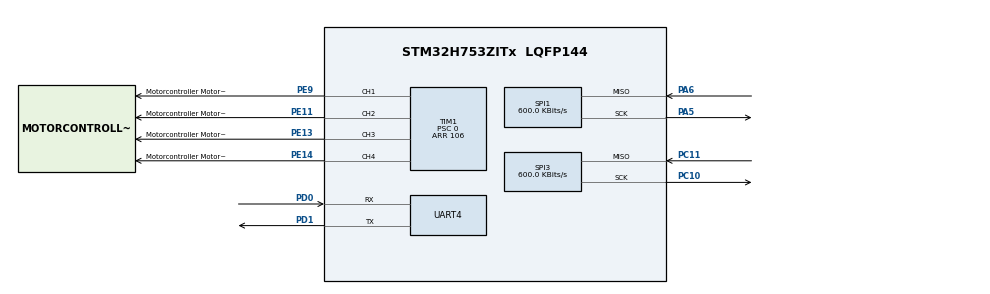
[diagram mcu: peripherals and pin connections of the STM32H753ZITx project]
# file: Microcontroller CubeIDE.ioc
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CORTEX_M7.CPU_DCache=Disabled
CORTEX_M7.CPU_ICache=Disabled
CORTEX_M7.MPU_Control=MPU_PRIVILEGED_DEFAULT
CORTEX_M7.default_mode_Activation=1
Dma.Request0=TIM1_CH1
Dma.Request1=TIM1_CH2
Dma.Request2=TIM1_CH3
Dma.Request3=TIM1_CH4
Dma.Request4=UART4_RX
Dma.TIM1_CH1.0.Direction=DMA_MEMORY_TO_PERIPH
Dma.TIM1_CH1.0.EventEnable=DISABLE
Dma.TIM1_CH1.0.FIFOMode=DMA_FIFOMODE_DISABLE
Dma.TIM1_CH1.0.Instance=DMA1_Stream0
Dma.TIM1_CH1.0.MemDataAlignment=DMA_MDATAALIGN_HALFWORD
Dma.TIM1_CH1.0.MemInc=DMA_MINC_ENABLE
Dma.TIM1_CH1.0.Mode=DMA_NORMAL
Dma.TIM1_CH1.0.PeriphDataAlignment=DMA_PDATAALIGN_HALFWORD
Dma.TIM1_CH1.0.PeriphInc=DMA_PINC_DISABLE
Dma.TIM1_CH1.0.Polarity=HAL_DMAMUX_REQ_GEN_RISING
Dma.TIM1_CH1.0.Priority=DMA_PRIORITY_VERY_HIGH
Dma.TIM1_CH1.0.RequestNumber=1
Dma.TIM1_CH1.0.SignalID=NONE
Dma.TIM1_CH1.0.SyncEnable=DISABLE
Dma.TIM1_CH1.0.SyncPolarity=HAL_DMAMUX_SYNC_NO_EVENT
Dma.TIM1_CH1.0.SyncRequestNumber=1
Dma.TIM1_CH1.0.SyncSignalID=NONE
Dma.TIM1_CH2.1.Direction=DMA_MEMORY_TO_PERIPH
Dma.TIM1_CH2.1.EventEnable=DISABLE
Dma.TIM1_CH2.1.FIFOMode=DMA_FIFOMODE_DISABLE
Dma.TIM1_CH2.1.Instance=DMA1_Stream1
Dma.TIM1_CH2.1.MemDataAlignment=DMA_MDATAALIGN_HALFWORD
Dma.TIM1_CH2.1.MemInc=DMA_MINC_ENABLE
Dma.TIM1_CH2.1.Mode=DMA_NORMAL
Dma.TIM1_CH2.1.PeriphDataAlignment=DMA_PDATAALIGN_HALFWORD
Dma.TIM1_CH2.1.PeriphInc=DMA_PINC_DISABLE
Dma.TIM1_CH2.1.Polarity=HAL_DMAMUX_REQ_GEN_RISING
Dma.TIM1_CH2.1.Priority=DMA_PRIORITY_VERY_HIGH
Dma.TIM1_CH2.1.RequestNumber=1
Dma.TIM1_CH2.1.SignalID=NONE
Dma.TIM1_CH2.1.SyncEnable=DISABLE
Dma.TIM1_CH2.1.SyncPolarity=HAL_DMAMUX_SYNC_NO_EVENT
Dma.TIM1_CH2.1.SyncRequestNumber=1
Dma.TIM1_CH2.1.SyncSignalID=NONE
Dma.TIM1_CH3.2.Direction=DMA_MEMORY_TO_PERIPH
Dma.TIM1_CH3.2.EventEnable=DISABLE
Dma.TIM1_CH3.2.FIFOMode=DMA_FIFOMODE_DISABLE
Dma.TIM1_CH3.2.Instance=DMA1_Stream2
Dma.TIM1_CH3.2.MemDataAlignment=DMA_MDATAALIGN_HALFWORD
Dma.TIM1_CH3.2.MemInc=DMA_MINC_ENABLE
Dma.TIM1_CH3.2.Mode=DMA_NORMAL
Dma.TIM1_CH3.2.PeriphDataAlignment=DMA_PDATAALIGN_HALFWORD
Dma.TIM1_CH3.2.PeriphInc=DMA_PINC_DISABLE
Dma.TIM1_CH3.2.Polarity=HAL_DMAMUX_REQ_GEN_RISING
Dma.TIM1_CH3.2.Priority=DMA_PRIORITY_VERY_HIGH
Dma.TIM1_CH3.2.RequestNumber=1
Dma.TIM1_CH3.2.SignalID=NONE
Dma.TIM1_CH3.2.SyncEnable=DISABLE
Dma.TIM1_CH3.2.SyncPolarity=HAL_DMAMUX_SYNC_NO_EVENT
Dma.TIM1_CH3.2.SyncRequestNumber=1
Dma.TIM1_CH3.2.SyncSignalID=NONE
Dma.TIM1_CH4.3.Direction=DMA_MEMORY_TO_PERIPH
Dma.TIM1_CH4.3.EventEnable=DISABLE
Dma.TIM1_CH4.3.FIFOMode=DMA_FIFOMODE_DISABLE
Dma.TIM1_CH4.3.Instance=DMA1_Stream3
Dma.TIM1_CH4.3.MemDataAlignment=DMA_MDATAALIGN_HALFWORD
Dma.TIM1_CH4.3.MemInc=DMA_MINC_ENABLE
Dma.TIM1_CH4.3.Mode=DMA_NORMAL
Dma.TIM1_CH4.3.PeriphDataAlignment=DMA_PDATAALIGN_HALFWORD
Dma.TIM1_CH4.3.PeriphInc=DMA_PINC_DISABLE
Dma.TIM1_CH4.3.Polarity=HAL_DMAMUX_REQ_GEN_RISING
Dma.TIM1_CH4.3.Priority=DMA_PRIORITY_VERY_HIGH
Dma.TIM1_CH4.3.RequestNumber=1
Dma.TIM1_CH4.3.SignalID=NONE
Dma.TIM1_CH4.3.SyncEnable=DISABLE
Dma.TIM1_CH4.3.SyncPolarity=HAL_DMAMUX_SYNC_NO_EVENT
Dma.TIM1_CH4.3.SyncRequestNumber=1
Dma.TIM1_CH4.3.SyncSignalID=NONE
Dma.UART4_RX.4.Direction=DMA_PERIPH_TO_MEMORY
Dma.UART4_RX.4.EventEnable=DISABLE
Dma.UART4_RX.4.FIFOMode=DMA_FIFOMODE_DISABLE
Dma.UART4_RX.4.Instance=DMA1_Stream4
Dma.UART4_RX.4.MemDataAlignment=DMA_MDATAALIGN_BYTE
Dma.UART4_RX.4.MemInc=DMA_MINC_ENABLE
Dma.UART4_RX.4.Mode=DMA_NORMAL
Dma.UART4_RX.4.PeriphDataAlignment=DMA_PDATAALIGN_BYTE
Dma.UART4_RX.4.PeriphInc=DMA_PINC_DISABLE
Dma.UART4_RX.4.Polarity=HAL_DMAMUX_REQ_GEN_RISING
Dma.UART4_RX.4.Priority=DMA_PRIORITY_MEDIUM
Dma.UART4_RX.4.RequestNumber=1
Dma.UART4_RX.4.SignalID=NONE
Dma.UART4_RX.4.SyncEnable=DISABLE
Dma.UART4_RX.4.SyncPolarity=HAL_DMAMUX_SYNC_NO_EVENT
Dma.UART4_RX.4.SyncRequestNumber=1
Dma.UART4_RX.4.SyncSignalID=NONE
FREERTOS.Tasks01=Main,24,512,RTOS_Main,Default,NULL,Dynamic,NULL,NULL;DShot,48,512,DShot_Task,Default,NULL,Dynamic,NULL,NULL;Weight,8,512,Weight_Task,Default,NULL,Dynamic,NULL,NULL;Terminal,24,512,Terminal_Task,Default,NULL,Dynamic,NULL,NULL
FREERTOS.configCHECK_FOR_STACK_OVERFLOW=2
FREERTOS.configUSE_NEWLIB_REENTRANT=1
Mcu.Family=STM32H7
Mcu.Name=STM32H753ZITx
Mcu.Package=LQFP144
NUCLEO-H753ZI.BUTTON=1
NUCLEO-H753ZI.LD1=true
NUCLEO-H753ZI.LD2=true
NUCLEO-H753ZI.LD3=true
NUCLEO-H753ZI.VCP=true
NVIC.DMA1_Stream0_IRQn=true\:5\:0\:false\:false\:true\:false\:false\:true\:true
NVIC.DMA1_Stream1_IRQn=true\:5\:0\:false\:false\:true\:false\:false\:true\:true
NVIC.DMA1_Stream2_IRQn=true\:5\:0\:false\:false\:true\:false\:false\:true\:true
NVIC.DMA1_Stream3_IRQn=true\:5\:0\:false\:false\:true\:false\:false\:true\:true
NVIC.DMA1_Stream4_IRQn=true\:5\:0\:false\:false\:true\:true\:false\:true\:true
NVIC.EXTI15_10_IRQn=true\:5\:0\:false\:false\:true\:true\:false\:true\:true
NVIC.PriorityGroup=NVIC_PRIORITYGROUP_4
NVIC.TIM7_IRQn=true\:15\:0\:false\:false\:true\:false\:false\:true\:true
NVIC.TimeBase=TIM7_IRQn
NVIC.TimeBaseIP=TIM7
NVIC.UART4_IRQn=true\:5\:0\:false\:false\:true\:true\:true\:true\:true
PA5.Mode=RX_Only_Simplex_Unidirect_Master
PA5.Signal=SPI1_SCK
PA6.Mode=RX_Only_Simplex_Unidirect_Master
PA6.Signal=SPI1_MISO
PB13.Signal=SPI2_SCK
PC10.Mode=RX_Only_Simplex_Unidirect_Master
PC10.Signal=SPI3_SCK
PC11.Mode=RX_Only_Simplex_Unidirect_Master
PC11.Signal=SPI3_MISO
PC14-OSC32_IN\ (OSC32_IN).Signal=RCC_OSC32_IN
PC15-OSC32_OUT\ (OSC32_OUT).Signal=RCC_OSC32_OUT
PD0.GPIO_PuPd=GPIO_PULLUP
PD0.Mode=Asynchronous
PD0.Signal=UART4_RX
PD1.Mode=Asynchronous
PD1.Signal=UART4_TX
PE11.GPIO_Label=Motorcontroller Motor 2- TIM1_CH2
PE11.GPIO_PuPd=GPIO_NOPULL
PE11.GPIO_Speed=GPIO_SPEED_FREQ_MEDIUM
PE11.Signal=S_TIM1_CH2
PE13.GPIO_Label=Motorcontroller Motor 3 - TIM1_CH3
PE13.GPIO_PuPd=GPIO_NOPULL
PE13.GPIO_Speed=GPIO_SPEED_FREQ_MEDIUM
PE13.Signal=S_TIM1_CH3
PE14.GPIO_Label=Motorcontroller Motor 4 - TIM1_CH4
PE14.GPIO_PuPd=GPIO_NOPULL
PE14.GPIO_Speed=GPIO_SPEED_FREQ_MEDIUM
PE14.Signal=S_TIM1_CH4
PE9.GPIO_Label=Motorcontroller Motor 1 - TIM1_CH1
PE9.GPIO_PuPd=GPIO_NOPULL
PE9.GPIO_Speed=GPIO_SPEED_FREQ_MEDIUM
PE9.Signal=S_TIM1_CH1
PH0-OSC_IN\ (PH0).Signal=RCC_OSC_IN
PH1-OSC_OUT\ (PH1).Signal=RCC_OSC_OUT
ProjectManager.HeapSize=0x200
ProjectManager.StackSize=0x400
ProjectManager.TargetToolchain=STM32CubeIDE
RCC.ADCFreq_Value=19200000
RCC.APB1Freq_Value=64000000
RCC.APB2Freq_Value=64000000
RCC.APB3Freq_Value=64000000
RCC.APB4Freq_Value=64000000
RCC.CortexFreq_Value=64000000
RCC.DIVM1=4
RCC.DIVM2=4
RCC.DIVM3=4
RCC.DIVN1=12
RCC.DIVN2=12
RCC.DIVN3=12
RCC.DIVP2=10
RCC.DIVQ1=10
RCC.DIVQ2=10
RCC.DIVQ3=10
RCC.HCLKFreq_Value=64000000
RCC.HSE_VALUE=8000000
RCC.PLL2FRACN=0
RCC.PLL3FRACN=0
RCC.PLLFRACN=0
RCC.PWR_Regulator_Voltage_Scale=PWR_REGULATOR_VOLTAGE_SCALE2
RCC.SYSCLKFreq_VALUE=64000000
RCC.Spi45ClockSelection=RCC_SPI45CLKSOURCE_PLL2
RCC.USBFreq_Value=19200000
SH.S_TIM1_CH1.0=TIM1_CH1,PWM Generation1 CH1
SH.S_TIM1_CH2.0=TIM1_CH2,PWM Generation2 CH2
SH.S_TIM1_CH3.0=TIM1_CH3,PWM Generation3 CH3
SH.S_TIM1_CH4.0=TIM1_CH4,PWM Generation4 CH4
SPI1.BaudRatePrescaler=SPI_BAUDRATEPRESCALER_32
SPI1.CLKPhase=SPI_PHASE_2EDGE
SPI1.CalculateBaudRate=600.0 KBits/s
SPI1.DataSize=SPI_DATASIZE_25BIT
SPI1.Direction=SPI_DIRECTION_2LINES_RXONLY
SPI1.MasterKeepIOState=SPI_MASTER_KEEP_IO_STATE_ENABLE
SPI1.Mode=SPI_MODE_MASTER
SPI1.NSSPMode=SPI_NSS_PULSE_DISABLE
SPI1.VirtualType=VM_MASTER
SPI3.BaudRatePrescaler=SPI_BAUDRATEPRESCALER_32
SPI3.CLKPhase=SPI_PHASE_2EDGE
SPI3.CalculateBaudRate=600.0 KBits/s
SPI3.DataSize=SPI_DATASIZE_25BIT
SPI3.Direction=SPI_DIRECTION_2LINES_RXONLY
SPI3.MasterKeepIOState=SPI_MASTER_KEEP_IO_STATE_ENABLE
SPI3.Mode=SPI_MODE_MASTER
SPI3.NSSPMode=SPI_NSS_PULSE_DISABLE
SPI3.VirtualType=VM_MASTER
TIM1.AutoReloadPreload=TIM_AUTORELOAD_PRELOAD_ENABLE
TIM1.AutomaticOutput=TIM_AUTOMATICOUTPUT_ENABLE
TIM1.Channel-PWM\ Generation1\ CH1=TIM_CHANNEL_1
TIM1.Channel-PWM\ Generation2\ CH2=TIM_CHANNEL_2
TIM1.Channel-PWM\ Generation3\ CH3=TIM_CHANNEL_3
TIM1.Channel-PWM\ Generation4\ CH4=TIM_CHANNEL_4
TIM1.OCIdleState_1=TIM_OCIDLESTATE_RESET
TIM1.OCPolarity_1=TIM_OCPOLARITY_HIGH
TIM1.OffStateIDLEMode=TIM_OSSI_ENABLE
TIM1.OffStateRunMode=TIM_OSSR_ENABLE
TIM1.Period=106
TIM1.Prescaler=0
TIM1.Pulse-PWM\ Generation1\ CH1=0
VP_FREERTOS_VS_CMSIS_V2.Mode=CMSIS_V2
VP_MEMORYMAP_VS_MEMORYMAP.Mode=CurAppReg
VP_NUCLEO-H753ZI_VS_BSP_COMMON.Mode=COMMON
VP_SYS_VS_tim7.Mode=TIM7
board=NUCLEO-H753ZI

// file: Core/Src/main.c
/* USER CODE BEGIN Header */
/**
  ******************************************************************************
  * @file           : main.c
  * @brief          : Main program body
  ******************************************************************************
  * @attention
  *
  * Copyright (c) 2026 STMicroelectronics.
  * All rights reserved.
  *
  * This software is licensed under terms that can be found in the LICENSE file
  * in the root directory of this software component.
  * If no LICENSE file comes with this software, it is provided AS-IS.
  *
  ******************************************************************************
  */
/* USER CODE END Header */
#include "main.h"
#include "FreeRTOS.h"
#include "cmsis_os2.h"

/* USER CODE BEGIN Includes */
#include "controller.h"
/* USER CODE END Includes */

COM_InitTypeDef BspCOMInit;

SPI_HandleTypeDef hspi1;
SPI_HandleTypeDef hspi3;

TIM_HandleTypeDef htim1;
DMA_HandleTypeDef hdma_tim1_ch1;
DMA_HandleTypeDef hdma_tim1_ch2;
DMA_HandleTypeDef hdma_tim1_ch3;
DMA_HandleTypeDef hdma_tim1_ch4;

UART_HandleTypeDef huart4;
DMA_HandleTypeDef hdma_uart4_rx;

/* Definitions for Main */
osThreadId_t MainHandle;
const osThreadAttr_t Main_attributes = {
  .name = "Main",
  .stack_size = 512 * 4,
  .priority = (osPriority_t) osPriorityNormal,
};
/* Definitions for DShot */
osThreadId_t DShotHandle;
const osThreadAttr_t DShot_attributes = {
  .name = "DShot",
  .stack_size = 512 * 4,
  .priority = (osPriority_t) osPriorityRealtime,
};
/* Definitions for Weight */
osThreadId_t WeightHandle;
const osThreadAttr_t Weight_attributes = {
  .name = "Weight",
  .stack_size = 512 * 4,
  .priority = (osPriority_t) osPriorityLow,
};
/* Definitions for Terminal */
osThreadId_t TerminalHandle;
const osThreadAttr_t Terminal_attributes = {
  .name = "Terminal",
  .stack_size = 512 * 4,
  .priority = (osPriority_t) osPriorityNormal,
};

void SystemClock_Config(void);
static void MPU_Config(void);
static void MX_GPIO_Init(void);
static void MX_DMA_Init(void);
static void MX_TIM1_Init(void);
static void MX_SPI1_Init(void);
static void MX_UART4_Init(void);
static void MX_SPI3_Init(void);
void RTOS_Main(void *argument);
void DShot_Task(void *argument);
void Weight_Task(void *argument);
void Terminal_Task(void *argument);

int main(void)
{

  /* MPU Configuration--------------------------------------------------------*/
  MPU_Config();

  /* MCU Configuration--------------------------------------------------------*/

  /* Reset of all peripherals, Initializes the Flash interface and the Systick. */
  HAL_Init();

  /* Configure the system clock */
  SystemClock_Config();

  /* Initialize all configured peripherals */
  MX_GPIO_Init();
  MX_DMA_Init();
  MX_TIM1_Init();
  MX_SPI1_Init();
  MX_UART4_Init();
  MX_SPI3_Init();

  /* Init scheduler */
  osKernelInitialize();

  /* Create the thread(s) */
  /* creation of Main */
  MainHandle = osThreadNew(RTOS_Main, NULL, &Main_attributes);

  /* creation of DShot */
  DShotHandle = osThreadNew(DShot_Task, NULL, &DShot_attributes);

  /* creation of Weight */
  WeightHandle = osThreadNew(Weight_Task, NULL, &Weight_attributes);

  /* creation of Terminal */
  TerminalHandle = osThreadNew(Terminal_Task, NULL, &Terminal_attributes);

  /* Initialize leds */
  BSP_LED_Init(LED_GREEN);
  BSP_LED_Init(LED_YELLOW);
  BSP_LED_Init(LED_RED);

  /* Initialize USER push-button, will be used to trigger an interrupt each time it's pressed.*/
  BSP_PB_Init(BUTTON_USER, BUTTON_MODE_EXTI);

  /* Initialize COM1 port (115200, 8 bits (7-bit data + 1 stop bit), no parity */
  BspCOMInit.BaudRate   = 115200;
  BspCOMInit.WordLength = COM_WORDLENGTH_8B;
  BspCOMInit.StopBits   = COM_STOPBITS_1;
  BspCOMInit.Parity     = COM_PARITY_NONE;
  BspCOMInit.HwFlowCtl  = COM_HWCONTROL_NONE;
  if (BSP_COM_Init(COM1, &BspCOMInit) != BSP_ERROR_NONE)
  {
    Error_Handler();
  }

  /* Start scheduler */
  osKernelStart();

  /* We should never get here as control is now taken by the scheduler */

  /* Infinite loop */
  while (1)
  {

  }
}

void SystemClock_Config(void)
{
  RCC_OscInitTypeDef RCC_OscInitStruct = {0};
  RCC_ClkInitTypeDef RCC_ClkInitStruct = {0};

  /** Supply configuration update enable
  */
  HAL_PWREx_ConfigSupply(PWR_LDO_SUPPLY);

  /** Configure the main internal regulator output voltage
  */
  __HAL_PWR_VOLTAGESCALING_CONFIG(PWR_REGULATOR_VOLTAGE_SCALE2);

  while(!__HAL_PWR_GET_FLAG(PWR_FLAG_VOSRDY)) {}

  /** Initializes the RCC Oscillators according to the specified parameters
  * in the RCC_OscInitTypeDef structure.
  */
  RCC_OscInitStruct.OscillatorType = RCC_OSCILLATORTYPE_HSI;
  RCC_OscInitStruct.HSIState = RCC_HSI_DIV1;
  RCC_OscInitStruct.HSICalibrationValue = RCC_HSICALIBRATION_DEFAULT;
  RCC_OscInitStruct.PLL.PLLState = RCC_PLL_ON;
  RCC_OscInitStruct.PLL.PLLSource = RCC_PLLSOURCE_HSI;
  RCC_OscInitStruct.PLL.PLLM = 4;
  RCC_OscInitStruct.PLL.PLLN = 12;
  RCC_OscInitStruct.PLL.PLLP = 2;
  RCC_OscInitStruct.PLL.PLLQ = 10;
  RCC_OscInitStruct.PLL.PLLR = 2;
  RCC_OscInitStruct.PLL.PLLRGE = RCC_PLL1VCIRANGE_3;
  RCC_OscInitStruct.PLL.PLLVCOSEL = RCC_PLL1VCOWIDE;
  RCC_OscInitStruct.PLL.PLLFRACN = 0;
  if (HAL_RCC_OscConfig(&RCC_OscInitStruct) != HAL_OK)
  {
    Error_Handler();
  }

  /** Initializes the CPU, AHB and APB buses clocks
  */
  RCC_ClkInitStruct.ClockType = RCC_CLOCKTYPE_HCLK|RCC_CLOCKTYPE_SYSCLK
                              |RCC_CLOCKTYPE_PCLK1|RCC_CLOCKTYPE_PCLK2
                              |RCC_CLOCKTYPE_D3PCLK1|RCC_CLOCKTYPE_D1PCLK1;
  RCC_ClkInitStruct.SYSCLKSource = RCC_SYSCLKSOURCE_HSI;
  RCC_ClkInitStruct.SYSCLKDivider = RCC_SYSCLK_DIV1;
  RCC_ClkInitStruct.AHBCLKDivider = RCC_HCLK_DIV1;
  RCC_ClkInitStruct.APB3CLKDivider = RCC_APB3_DIV1;
  RCC_ClkInitStruct.APB1CLKDivider = RCC_APB1_DIV1;
  RCC_ClkInitStruct.APB2CLKDivider = RCC_APB2_DIV1;
  RCC_ClkInitStruct.APB4CLKDivider = RCC_APB4_DIV1;

  if (HAL_RCC_ClockConfig(&RCC_ClkInitStruct, FLASH_LATENCY_1) != HAL_OK)
  {
    Error_Handler();
  }
}

static void MX_SPI1_Init(void)
{

  /* SPI1 parameter configuration*/
  hspi1.Instance = SPI1;
  hspi1.Init.Mode = SPI_MODE_MASTER;
  hspi1.Init.Direction = SPI_DIRECTION_2LINES_RXONLY;
  hspi1.Init.DataSize = SPI_DATASIZE_25BIT;
  hspi1.Init.CLKPolarity = SPI_POLARITY_LOW;
  hspi1.Init.CLKPhase = SPI_PHASE_2EDGE;
  hspi1.Init.NSS = SPI_NSS_SOFT;
  hspi1.Init.BaudRatePrescaler = SPI_BAUDRATEPRESCALER_32;
  hspi1.Init.FirstBit = SPI_FIRSTBIT_MSB;
  hspi1.Init.TIMode = SPI_TIMODE_DISABLE;
  hspi1.Init.CRCCalculation = SPI_CRCCALCULATION_DISABLE;
  hspi1.Init.CRCPolynomial = 0x0;
  hspi1.Init.NSSPMode = SPI_NSS_PULSE_DISABLE;
  hspi1.Init.NSSPolarity = SPI_NSS_POLARITY_LOW;
  hspi1.Init.FifoThreshold = SPI_FIFO_THRESHOLD_01DATA;
  hspi1.Init.TxCRCInitializationPattern = SPI_CRC_INITIALIZATION_ALL_ZERO_PATTERN;
  hspi1.Init.RxCRCInitializationPattern = SPI_CRC_INITIALIZATION_ALL_ZERO_PATTERN;
  hspi1.Init.MasterSSIdleness = SPI_MASTER_SS_IDLENESS_00CYCLE;
  hspi1.Init.MasterInterDataIdleness = SPI_MASTER_INTERDATA_IDLENESS_00CYCLE;
  hspi1.Init.MasterReceiverAutoSusp = SPI_MASTER_RX_AUTOSUSP_DISABLE;
  hspi1.Init.MasterKeepIOState = SPI_MASTER_KEEP_IO_STATE_ENABLE;
  hspi1.Init.IOSwap = SPI_IO_SWAP_DISABLE;
  if (HAL_SPI_Init(&hspi1) != HAL_OK)
  {
    Error_Handler();
  }

}

static void MX_SPI3_Init(void)
{

  /* SPI3 parameter configuration*/
  hspi3.Instance = SPI3;
  hspi3.Init.Mode = SPI_MODE_MASTER;
  hspi3.Init.Direction = SPI_DIRECTION_2LINES_RXONLY;
  hspi3.Init.DataSize = SPI_DATASIZE_25BIT;
  hspi3.Init.CLKPolarity = SPI_POLARITY_LOW;
  hspi3.Init.CLKPhase = SPI_PHASE_2EDGE;
  hspi3.Init.NSS = SPI_NSS_SOFT;
  hspi3.Init.BaudRatePrescaler = SPI_BAUDRATEPRESCALER_32;
  hspi3.Init.FirstBit = SPI_FIRSTBIT_MSB;
  hspi3.Init.TIMode = SPI_TIMODE_DISABLE;
  hspi3.Init.CRCCalculation = SPI_CRCCALCULATION_DISABLE;
  hspi3.Init.CRCPolynomial = 0x0;
  hspi3.Init.NSSPMode = SPI_NSS_PULSE_DISABLE;
  hspi3.Init.NSSPolarity = SPI_NSS_POLARITY_LOW;
  hspi3.Init.FifoThreshold = SPI_FIFO_THRESHOLD_01DATA;
  hspi3.Init.TxCRCInitializationPattern = SPI_CRC_INITIALIZATION_ALL_ZERO_PATTERN;
  hspi3.Init.RxCRCInitializationPattern = SPI_CRC_INITIALIZATION_ALL_ZERO_PATTERN;
  hspi3.Init.MasterSSIdleness = SPI_MASTER_SS_IDLENESS_00CYCLE;
  hspi3.Init.MasterInterDataIdleness = SPI_MASTER_INTERDATA_IDLENESS_00CYCLE;
  hspi3.Init.MasterReceiverAutoSusp = SPI_MASTER_RX_AUTOSUSP_DISABLE;
  hspi3.Init.MasterKeepIOState = SPI_MASTER_KEEP_IO_STATE_ENABLE;
  hspi3.Init.IOSwap = SPI_IO_SWAP_DISABLE;
  if (HAL_SPI_Init(&hspi3) != HAL_OK)
  {
    Error_Handler();
  }

}

static void MX_TIM1_Init(void)
{

  TIM_MasterConfigTypeDef sMasterConfig = {0};
  TIM_OC_InitTypeDef sConfigOC = {0};
  TIM_BreakDeadTimeConfigTypeDef sBreakDeadTimeConfig = {0};

  htim1.Instance = TIM1;
  htim1.Init.Prescaler = 0;
  htim1.Init.CounterMode = TIM_COUNTERMODE_UP;
  htim1.Init.Period = 106;
  htim1.Init.ClockDivision = TIM_CLOCKDIVISION_DIV1;
  htim1.Init.RepetitionCounter = 0;
  htim1.Init.AutoReloadPreload = TIM_AUTORELOAD_PRELOAD_ENABLE;
  if (HAL_TIM_PWM_Init(&htim1) != HAL_OK)
  {
    Error_Handler();
  }
  sMasterConfig.MasterOutputTrigger = TIM_TRGO_RESET;
  sMasterConfig.MasterOutputTrigger2 = TIM_TRGO2_RESET;
  sMasterConfig.MasterSlaveMode = TIM_MASTERSLAVEMODE_DISABLE;
  if (HAL_TIMEx_MasterConfigSynchronization(&htim1, &sMasterConfig) != HAL_OK)
  {
    Error_Handler();
  }
  sConfigOC.OCMode = TIM_OCMODE_PWM1;
  sConfigOC.Pulse = 0;
  sConfigOC.OCPolarity = TIM_OCPOLARITY_HIGH;
  sConfigOC.OCNPolarity = TIM_OCNPOLARITY_HIGH;
  sConfigOC.OCFastMode = TIM_OCFAST_DISABLE;
  sConfigOC.OCIdleState = TIM_OCIDLESTATE_RESET;
  sConfigOC.OCNIdleState = TIM_OCNIDLESTATE_RESET;
  if (HAL_TIM_PWM_ConfigChannel(&htim1, &sConfigOC, TIM_CHANNEL_1) != HAL_OK)
  {
    Error_Handler();
  }
  if (HAL_TIM_PWM_ConfigChannel(&htim1, &sConfigOC, TIM_CHANNEL_2) != HAL_OK)
  {
    Error_Handler();
  }
  if (HAL_TIM_PWM_ConfigChannel(&htim1, &sConfigOC, TIM_CHANNEL_3) != HAL_OK)
  {
    Error_Handler();
  }
  if (HAL_TIM_PWM_ConfigChannel(&htim1, &sConfigOC, TIM_CHANNEL_4) != HAL_OK)
  {
    Error_Handler();
  }
  sBreakDeadTimeConfig.OffStateRunMode = TIM_OSSR_ENABLE;
  sBreakDeadTimeConfig.OffStateIDLEMode = TIM_OSSI_ENABLE;
  sBreakDeadTimeConfig.LockLevel = TIM_LOCKLEVEL_OFF;
  sBreakDeadTimeConfig.DeadTime = 0;
  sBreakDeadTimeConfig.BreakState = TIM_BREAK_DISABLE;
  sBreakDeadTimeConfig.BreakPolarity = TIM_BREAKPOLARITY_HIGH;
  sBreakDeadTimeConfig.BreakFilter = 0;
  sBreakDeadTimeConfig.Break2State = TIM_BREAK2_DISABLE;
  sBreakDeadTimeConfig.Break2Polarity = TIM_BREAK2POLARITY_HIGH;
  sBreakDeadTimeConfig.Break2Filter = 0;
  sBreakDeadTimeConfig.AutomaticOutput = TIM_AUTOMATICOUTPUT_ENABLE;
  if (HAL_TIMEx_ConfigBreakDeadTime(&htim1, &sBreakDeadTimeConfig) != HAL_OK)
  {
    Error_Handler();
  }
  HAL_TIM_MspPostInit(&htim1);

}

static void MX_UART4_Init(void)
{

  huart4.Instance = UART4;
  huart4.Init.BaudRate = 115200;
  huart4.Init.WordLength = UART_WORDLENGTH_8B;
  huart4.Init.StopBits = UART_STOPBITS_1;
  huart4.Init.Parity = UART_PARITY_NONE;
  huart4.Init.Mode = UART_MODE_TX_RX;
  huart4.Init.HwFlowCtl = UART_HWCONTROL_NONE;
  huart4.Init.OverSampling = UART_OVERSAMPLING_16;
  huart4.Init.OneBitSampling = UART_ONE_BIT_SAMPLE_DISABLE;
  huart4.Init.ClockPrescaler = UART_PRESCALER_DIV1;
  huart4.AdvancedInit.AdvFeatureInit = UART_ADVFEATURE_NO_INIT;
  if (HAL_UART_Init(&huart4) != HAL_OK)
  {
    Error_Handler();
  }
  if (HAL_UARTEx_SetTxFifoThreshold(&huart4, UART_TXFIFO_THRESHOLD_1_8) != HAL_OK)
  {
    Error_Handler();
  }
  if (HAL_UARTEx_SetRxFifoThreshold(&huart4, UART_RXFIFO_THRESHOLD_1_8) != HAL_OK)
  {
    Error_Handler();
  }
  if (HAL_UARTEx_DisableFifoMode(&huart4) != HAL_OK)
  {
    Error_Handler();
  }

}

static void MX_DMA_Init(void)
{

  /* DMA controller clock enable */
  __HAL_RCC_DMA1_CLK_ENABLE();

  /* DMA interrupt init */
  /* DMA1_Stream0_IRQn interrupt configuration */
  HAL_NVIC_SetPriority(DMA1_Stream0_IRQn, 5, 0);
  HAL_NVIC_EnableIRQ(DMA1_Stream0_IRQn);
  /* DMA1_Stream1_IRQn interrupt configuration */
  HAL_NVIC_SetPriority(DMA1_Stream1_IRQn, 5, 0);
  HAL_NVIC_EnableIRQ(DMA1_Stream1_IRQn);
  /* DMA1_Stream2_IRQn interrupt configuration */
  HAL_NVIC_SetPriority(DMA1_Stream2_IRQn, 5, 0);
  HAL_NVIC_EnableIRQ(DMA1_Stream2_IRQn);
  /* DMA1_Stream3_IRQn interrupt configuration */
  HAL_NVIC_SetPriority(DMA1_Stream3_IRQn, 5, 0);
  HAL_NVIC_EnableIRQ(DMA1_Stream3_IRQn);
  /* DMA1_Stream4_IRQn interrupt configuration */
  HAL_NVIC_SetPriority(DMA1_Stream4_IRQn, 5, 0);
  HAL_NVIC_EnableIRQ(DMA1_Stream4_IRQn);

}

static void MX_GPIO_Init(void)
{
  GPIO_InitTypeDef GPIO_InitStruct = {0};

  /* GPIO Ports Clock Enable */
  __HAL_RCC_GPIOC_CLK_ENABLE();
  __HAL_RCC_GPIOH_CLK_ENABLE();
  __HAL_RCC_GPIOA_CLK_ENABLE();
  __HAL_RCC_GPIOE_CLK_ENABLE();
  __HAL_RCC_GPIOB_CLK_ENABLE();
  __HAL_RCC_GPIOD_CLK_ENABLE();

  /*Configure GPIO pin : PB13 */
  GPIO_InitStruct.Pin = GPIO_PIN_13;
  GPIO_InitStruct.Mode = GPIO_MODE_AF_PP;
  GPIO_InitStruct.Pull = GPIO_NOPULL;
  GPIO_InitStruct.Speed = GPIO_SPEED_FREQ_LOW;
  GPIO_InitStruct.Alternate = GPIO_AF5_SPI2;
  HAL_GPIO_Init(GPIOB, &GPIO_InitStruct);

}

void RTOS_Main(void *argument)
{
  /* USER CODE BEGIN 5 */
	controller_init();
  /* Infinite loop */
  for(;;)
  {
	  osDelay(controller_main());
  }
  /* USER CODE END 5 */
}

void DShot_Task(void *argument)
{
  /* USER CODE BEGIN DShot_Task */
  /* Infinite loop */
  for(;;)
  {
	  osDelay(controller_dshot());
  }
  /* USER CODE END DShot_Task */
}

void Weight_Task(void *argument)
{
  /* USER CODE BEGIN Weight_Task */
  /* Infinite loop */
  for(;;)
  {
	  osDelay(controller_weight());
  }
  /* USER CODE END Weight_Task */
}

void Terminal_Task(void *argument)
{
  /* USER CODE BEGIN Terminal_Task */
  /* Infinite loop */
  for(;;)
  {
    osDelay(controller_terminal());
  }
  /* USER CODE END Terminal_Task */
}

 /* MPU Configuration */

void MPU_Config(void)
{
  MPU_Region_InitTypeDef MPU_InitStruct = {0};

  /* Disables the MPU */
  HAL_MPU_Disable();

  /** Initializes and configures the Region and the memory to be protected
  */
  MPU_InitStruct.Enable = MPU_REGION_ENABLE;
  MPU_InitStruct.Number = MPU_REGION_NUMBER0;
  MPU_InitStruct.BaseAddress = 0x0;
  MPU_InitStruct.Size = MPU_REGION_SIZE_4GB;
  MPU_InitStruct.SubRegionDisable = 0x87;
  MPU_InitStruct.TypeExtField = MPU_TEX_LEVEL0;
  MPU_InitStruct.AccessPermission = MPU_REGION_NO_ACCESS;
  MPU_InitStruct.DisableExec = MPU_INSTRUCTION_ACCESS_DISABLE;
  MPU_InitStruct.IsShareable = MPU_ACCESS_SHAREABLE;
  MPU_InitStruct.IsCacheable = MPU_ACCESS_NOT_CACHEABLE;
  MPU_InitStruct.IsBufferable = MPU_ACCESS_NOT_BUFFERABLE;

  HAL_MPU_ConfigRegion(&MPU_InitStruct);
  /* Enables the MPU */
  HAL_MPU_Enable(MPU_PRIVILEGED_DEFAULT);

}

void HAL_TIM_PeriodElapsedCallback(TIM_HandleTypeDef *htim)
{
  if (htim->Instance == TIM7)
  {
    HAL_IncTick();
  }
}

void Error_Handler(void)
{
  __disable_irq();
  while (1)
  {
  }
}

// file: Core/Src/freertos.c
/* USER CODE BEGIN Header */
/**
  ******************************************************************************
  * File Name          : freertos.c
  * Description        : Code for freertos applications
  ******************************************************************************
  * @attention
  *
  * Copyright (c) 2026 STMicroelectronics.
  * All rights reserved.
  *
  * This software is licensed under terms that can be found in the LICENSE file
  * in the root directory of this software component.
  * If no LICENSE file comes with this software, it is provided AS-IS.
  *
  ******************************************************************************
  */
/* USER CODE END Header */

#include "FreeRTOS.h"
#include "task.h"
#include "main.h"

/* Hook prototypes */
void vApplicationStackOverflowHook(xTaskHandle xTask, char *pcTaskName);

/* USER CODE BEGIN 4 */
void vApplicationStackOverflowHook(xTaskHandle xTask, char *pcTaskName)
{
   /* Run time stack overflow checking is performed if
   configCHECK_FOR_STACK_OVERFLOW is defined to 1 or 2. This hook function is
   called if a stack overflow is detected. */
}
/* USER CODE END 4 */
